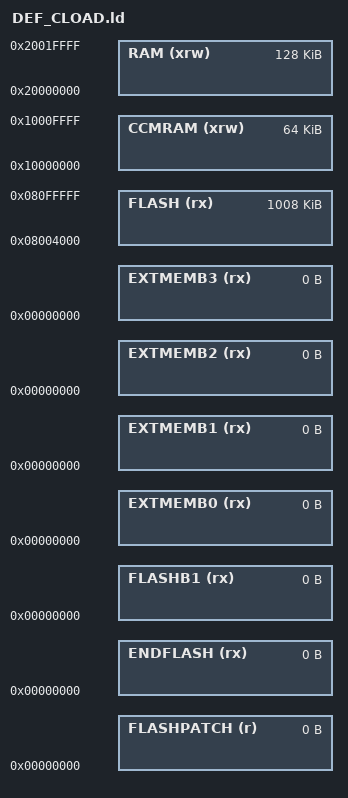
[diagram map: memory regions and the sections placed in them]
/*
Linker subscript for STM32F405 definitions with 1M Flash and 128K RAM
Copyright RAISONANCE 2007-2009
!!! This file is automatically generated by Ride !!!
Do not modify it, as it will be erased at every link.
You can use, copy and distribute this file freely, but without any waranty.
*/

/* Memory Spaces Definitions */

MEMORY
{
  RAM (xrw) : ORIGIN = 0x20000000, LENGTH = 128K
  CCMRAM (xrw) : ORIGIN = 0x10000000, LENGTH = 64K
  FLASH (rx) : ORIGIN = 0x8004000, LENGTH = 1008K
  FLASHPATCH (r) : ORIGIN = 0x00000000, LENGTH = 0
  ENDFLASH (rx)  : ORIGIN = 0x00000000, LENGTH = 0
  FLASHB1  (rx)  : ORIGIN = 0x00000000, LENGTH = 0
  EXTMEMB0 (rx)  : ORIGIN = 0x00000000, LENGTH = 0
  EXTMEMB1 (rx)  : ORIGIN = 0x00000000, LENGTH = 0
  EXTMEMB2 (rx)  : ORIGIN = 0x00000000, LENGTH = 0
  EXTMEMB3 (rx)  : ORIGIN = 0x00000000, LENGTH = 0
}

/* higher address of the user mode stack */
_estack = 0x2001FFFF;
